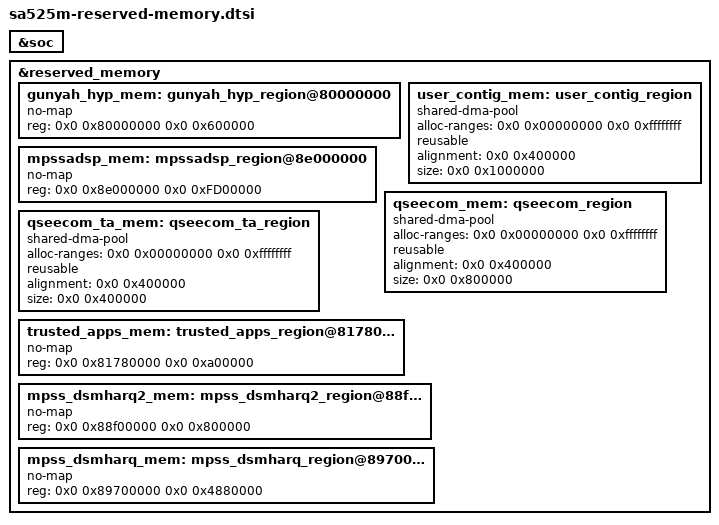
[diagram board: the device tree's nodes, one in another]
// SPDX-License-Identifier: BSD-3-Clause
/*
 * Copyright (c) Qualcomm Technologies, Inc. and/or its subsidiaries.
 */

/ {
};

&soc {
};

&reserved_memory {
	gunyah_hyp_mem: gunyah_hyp_region@80000000 {
		no-map;
		reg = <0x0 0x80000000 0x0 0x600000>;
	};

	mpssadsp_mem: mpssadsp_region@8e000000 {
		no-map;
		reg = <0x0 0x8e000000 0x0 0xFD00000>;
	};

	user_contig_mem: user_contig_region {
		compatible = "shared-dma-pool";
		alloc-ranges = <0x0 0x00000000 0x0 0xffffffff>;
		reusable;
		alignment = <0x0 0x400000>;
		size = <0x0 0x1000000>;
	};

	qseecom_mem: qseecom_region {
		compatible = "shared-dma-pool";
		alloc-ranges = <0x0 0x00000000 0x0 0xffffffff>;
		reusable;
		alignment = <0x0 0x400000>;
		size = <0x0 0x800000>;
	};

	qseecom_ta_mem: qseecom_ta_region {
		compatible = "shared-dma-pool";
		alloc-ranges = <0x0 0x00000000 0x0 0xffffffff>;
		reusable;
		alignment = <0x0 0x400000>;
		size = <0x0 0x400000>;
	};

	trusted_apps_mem: trusted_apps_region@81780000 {
		no-map;
		reg = <0x0 0x81780000 0x0 0xa00000>;
	};

	mpss_dsmharq2_mem: mpss_dsmharq2_region@88f00000 {
		no-map;
		reg = <0x0 0x88f00000 0x0 0x800000>;
	};

	/delete-node/  mpss_dsmharq_region@8b400000;
	mpss_dsmharq_mem: mpss_dsmharq_region@89700000 {
		no-map;
		reg = <0x0 0x89700000 0x0 0x4880000>;
	};

	/delete-node/  hyp_elf_package_region@80800000;

	/delete-node/ llcc_tcm_region@15800000;

};

